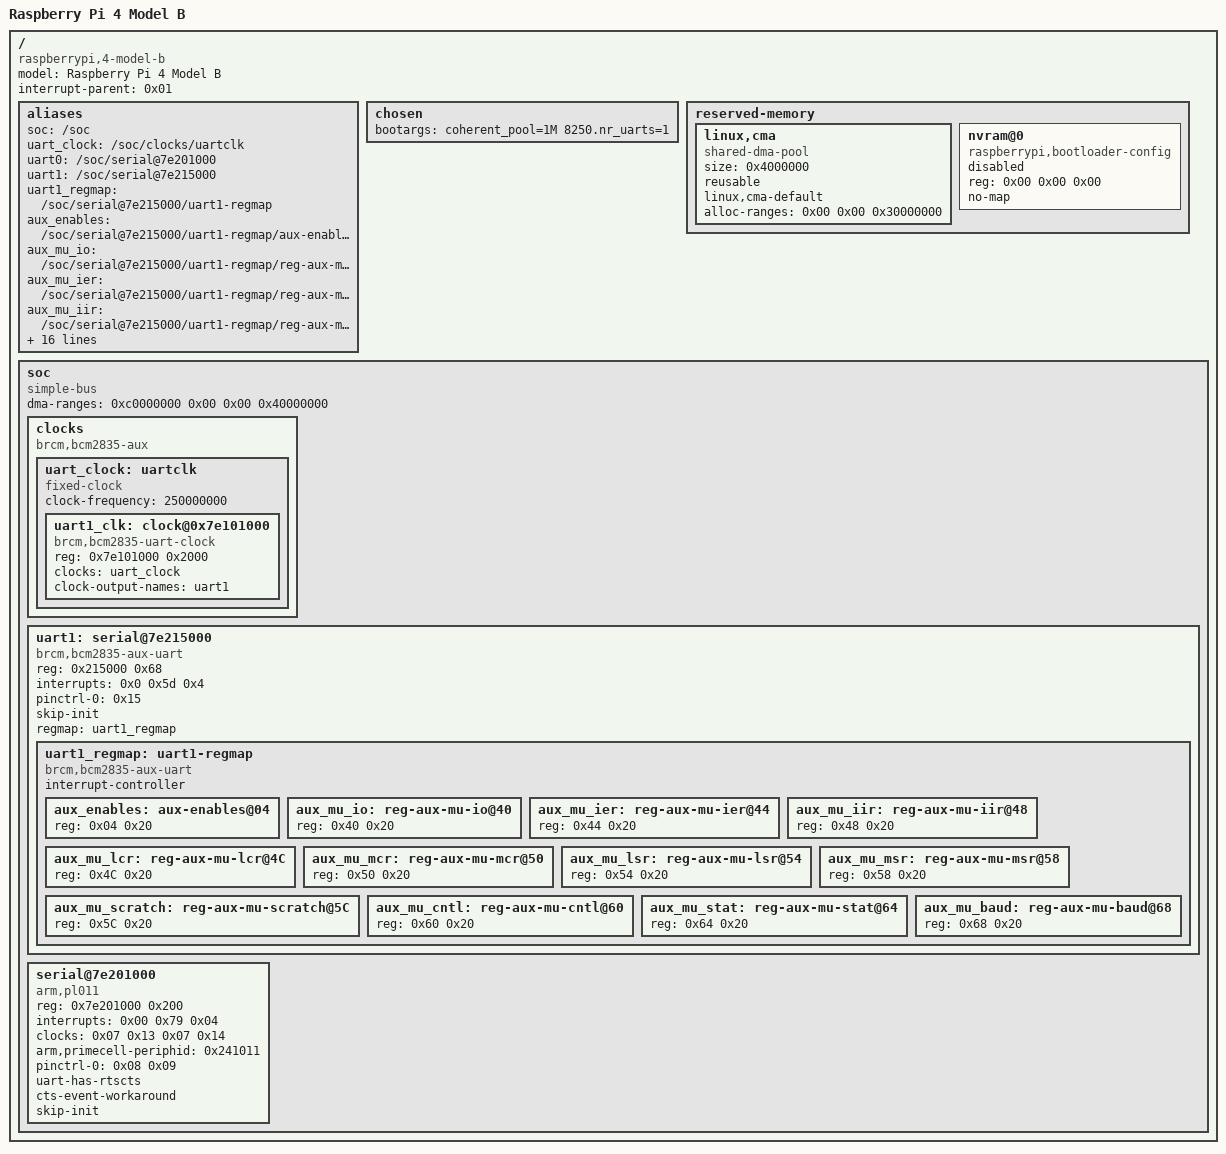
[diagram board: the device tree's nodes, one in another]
/dts-v1/;

/memreserve/	0x0000000000000000 0x0000000000001000;
/ {
	compatible = "raspberrypi,4-model-b\0brcm,bcm2711";
	model = "Raspberry Pi 4 Model B";
	#address-cells = <0x02>;
	#size-cells = <0x01>;
	interrupt-parent = <0x01>;

	aliases {
		soc = "/soc";
		uart_clock = "/soc/clocks/uartclk";
		uart0 = "/soc/serial@7e201000";
		uart1 = "/soc/serial@7e215000";
		uart1_regmap = "/soc/serial@7e215000/uart1-regmap";
		aux_enables = "/soc/serial@7e215000/uart1-regmap/aux-enables@04";
		aux_mu_io = "/soc/serial@7e215000/uart1-regmap/reg-aux-mu-io@40";
		aux_mu_ier = "/soc/serial@7e215000/uart1-regmap/reg-aux-mu-ier@44";
		aux_mu_iir = "/soc/serial@7e215000/uart1-regmap/reg-aux-mu-iir@48";
		aux_mu_lcr = "/soc/serial@7e215000/uart1-regmap/reg-aux-mu-lcr@4C";
		aux_mu_mcr = "/soc/serial@7e215000/uart1-regmap/reg-aux-mu-mcr@50";
		aux_mu_lsr = "/soc/serial@7e215000/uart1-regmap/reg-aux-mu-lsr@54";
		aux_mu_msr = "/soc/serial@7e215000/uart1-regmap/reg-aux-mu-msr@58";
		aux_mu_scratch = "/soc/serial@7e215000/uart1-regmap/reg-aux-mu-scratch@5C";
		aux_mu_cntl = "/soc/serial@7e215000/uart1-regmap/reg-aux-mu-cntl@60";
		aux_mu_stat = "/soc/serial@7e215000/uart1-regmap/reg-aux-mu-stat@64";
		aux_mu_baud = "/soc/serial@7e215000/uart1-regmap/reg-aux-mu-baud@68";
	};

	chosen {
		bootargs = "coherent_pool=1M 8250.nr_uarts=1";
	};

	reserved-memory {
		#address-cells = <0x02>;
		#size-cells = <0x01>;
		ranges;
		phandle = <0x41>;

		linux,cma {
			compatible = "shared-dma-pool";
			size = <0x4000000>;
			reusable;
			linux,cma-default;
			alloc-ranges = <0x00 0x00 0x30000000>;
			phandle = <0x42>;
		};

		nvram@0 {
			compatible = "raspberrypi,bootloader-config\0nvmem-rmem";
			#address-cells = <0x01>;
			#size-cells = <0x01>;
			reg = <0x00 0x00 0x00>;
			no-map;
			status = "disabled";
			phandle = <0x43>;
		};
	};


	soc {
		compatible = "simple-bus";
		#address-cells = <0x01>;
		#size-cells = <0x01>;
		ranges = <0x7e000000 0x00 0xfe000000 0x1800000 0x7c000000 0x00 0xfc000000 0x2000000 0x40000000 0x00 0xff800000 0x800000>;
		dma-ranges = <0xc0000000 0x00 0x00 0x40000000>;
		phandle = <0x45>;

		clocks{
			compatible = "brcm,bcm2835-aux";
    		#clock-cells = <1>;

			uart_clock: uartclk {
				compatible = "fixed-clock";
				#clock-cells = <1>;
				clock-frequency = "250000000"; // Frecuencia del reloj en Hz 250000000

				// Propiedades específicas del UART1
				uart1_clk: clock@0x7e101000 {
					compatible = "brcm,bcm2835-uart-clock";
					reg = <0x7e101000 0x2000>; // Inserta el índice del registro de configuración del reloj del UART1
					clocks = <&uart_clock>;
					clock-output-names = "uart1";
				};
			};
		};


		uart1: serial@7e215000 {
			#address-cells = <1>;
            #size-cells = <2>;
			
			compatible = "brcm,bcm2835-aux-uart"; // indica el controlador o driver compatible con el dispositivo, en este caso del uart.
			reg = <0x215000 0x68>; // rango de direcciones disponibles, en este caso son las direcciones usadas para el uart1.
			interrupts = <0x0 0x5d 0x4>; //La sintaxis utilizada es <interrupt-controller-id> <interrupt-id> <interrupt-flag>
				
				/**
				<interrupt-controller-id>: 0x0. Esto indica el identificador del controlador de interrupciones al que está conectado el UART.
				<interrupt-id>: 0x5d. Este es el número de identificación de la interrupción específica del UART.
				<interrupt-flag>: 0x4. Indica el tipo de interrupción o su configuración adicional.
				*/

			status = "okay";
			pinctrl-names = "default";
			pinctrl-0 = <0x15>;
			skip-init;
			phandle = <0x31>;

			regmap = <&uart1_regmap>;

			uart1_regmap: uart1-regmap {
				compatible = "brcm,bcm2835-aux-uart";
				#address-cells = <1>;
				#size-cells = <1>;
				interrupt-controller;
				#interrupt-cells = <1>;

				aux_enables: aux-enables@04 {
					reg = <0x04 0x20>;
				};

				aux_mu_io: reg-aux-mu-io@40 {
					reg = <0x40 0x20>;
				};

				aux_mu_ier: reg-aux-mu-ier@44 {
					reg = <0x44 0x20>;
				};

				aux_mu_iir: reg-aux-mu-iir@48 {
					reg = <0x48 0x20>;
				};

				aux_mu_lcr: reg-aux-mu-lcr@4C {
					reg = <0x4C 0x20>;
				};

				aux_mu_mcr: reg-aux-mu-mcr@50 {
					reg = <0x50 0x20>;
				};

				aux_mu_lsr: reg-aux-mu-lsr@54 {
					reg = <0x54 0x20>;
				};

				aux_mu_msr: reg-aux-mu-msr@58 {
					reg = <0x58 0x20>;
				};

				aux_mu_scratch: reg-aux-mu-scratch@5C {
					reg = <0x5C 0x20>;
				};

				aux_mu_cntl: reg-aux-mu-cntl@60 {
					reg = <0x60 0x20>;
				};

				aux_mu_stat: reg-aux-mu-stat@64 {
					reg = <0x64 0x20>;
				};

				aux_mu_baud: reg-aux-mu-baud@68 {
					reg = <0x68 0x20>;
				};
			};
		};


		serial@7e201000 {
			compatible = "arm,pl011\0arm,primecell";
			reg = <0x7e201000 0x200>;
			interrupts = <0x00 0x79 0x04>;
			clocks = <0x07 0x13 0x07 0x14>;
			clock-names = "uartclk\0apb_pclk";
			arm,primecell-periphid = <0x241011>;
			pinctrl-names = "default";
			pinctrl-0 = <0x08 0x09>;
			uart-has-rtscts;
			status = "okay";
			cts-event-workaround;
			skip-init;
			phandle = <0x30>;

		};

	};


	// VER SI AÑADIR A OVERRIDES Y A SYMBOLS

	__overrides__ {
		uart1 = "\0\0\01status";
	};


	__symbols__ {
		rmem = "/reserved-memory";
		soc = "/soc";
		uart1 = "/soc/serial@7e215000";
	};
};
